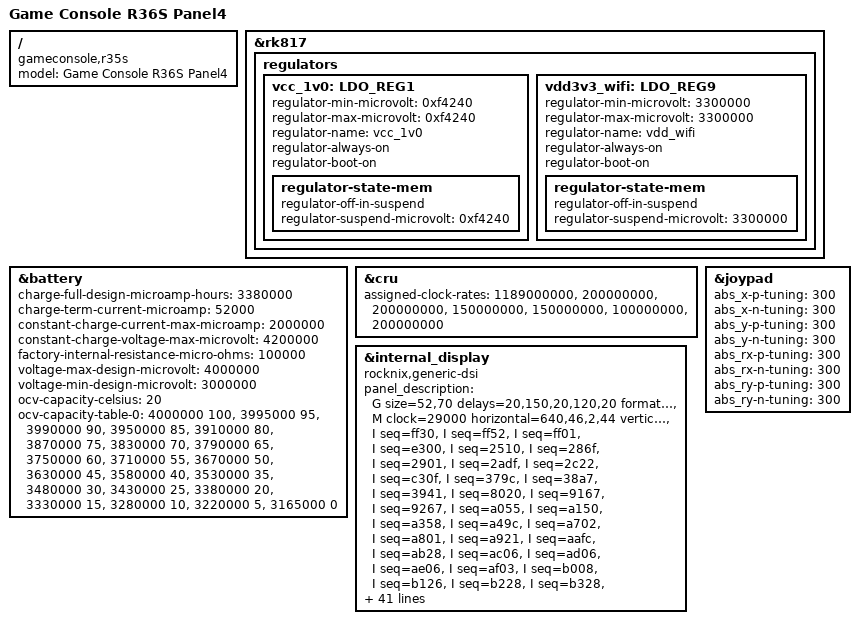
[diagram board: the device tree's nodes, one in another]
// SPDX-License-Identifier: (GPL-2.0+ OR MIT)
/*
* # Copyright (C) 2022-26 AURKNIX (https://github.com/AveyondFly)
*/

/dts-v1/;
#include "rk3326-gameconsole-r36s.dts"

/ {
	model = "Game Console R36S Panel4";
	compatible = "gameconsole,r35s", "gameconsole,r36s", "rockchip,rk3326";
};

&rk817 {
	regulators{
		vcc_1v0: LDO_REG1 {
			regulator-min-microvolt = <0xf4240>;
			regulator-max-microvolt = <0xf4240>;
			regulator-name = "vcc_1v0";
			regulator-always-on;
			regulator-boot-on;
			
			regulator-state-mem {
				regulator-off-in-suspend;
				regulator-suspend-microvolt = <0xf4240>;
			};
		};
		vdd3v3_wifi: LDO_REG9 {
			regulator-min-microvolt = <3300000>;
			regulator-max-microvolt = <3300000>;
			regulator-name = "vdd_wifi";
			regulator-always-on;
			regulator-boot-on;
			
			regulator-state-mem {
				regulator-off-in-suspend;
				regulator-suspend-microvolt = <3300000>;
			};
		};
	};
};

&battery {
	charge-full-design-microamp-hours = <3380000>;
	charge-term-current-microamp = <52000>;
	constant-charge-current-max-microamp = <2000000>;
	constant-charge-voltage-max-microvolt = <4200000>;
	factory-internal-resistance-micro-ohms = <100000>;
	voltage-max-design-microvolt = <4000000>;
	voltage-min-design-microvolt = <3000000>;

	ocv-capacity-celsius = <20>;
	ocv-capacity-table-0 = <4000000 100>, <3995000 95>, <3990000 90>, <3950000 85>,
		<3910000 80>, <3870000 75>, <3830000 70>, <3790000 65>,
		<3750000 60>, <3710000 55>, <3670000 50>, <3630000 45>,
		<3580000 40>, <3530000 35>, <3480000 30>, <3430000 25>,
		<3380000 20>, <3330000 15>, <3280000 10>, <3220000 5>,
		<3165000 0>;
};

&cru {
	assigned-clock-rates = <1189000000>,
	<200000000>, <200000000>,
	<150000000>, <150000000>,
	<100000000>, <200000000>;
};

&joypad {
	abs_x-p-tuning = <300>;
	abs_x-n-tuning = <300>;
	abs_y-p-tuning = <300>;
	abs_y-n-tuning = <300>;

	abs_rx-p-tuning = <300>;
	abs_rx-n-tuning = <300>;
	abs_ry-p-tuning = <300>;
	abs_ry-n-tuning = <300>;

};

&internal_display {
	compatible = "rocknix,generic-dsi";
	panel_description = 
	"G size=52,70 delays=20,150,20,120,20 format=rgb888 lanes=4 flags=0xe03",

	"M clock=29000 horizontal=640,46,2,44 vertical=480,165,2,13 default=1",

	"I seq=ff30",
	"I seq=ff52",
	"I seq=ff01",
	"I seq=e300",
	"I seq=2510",
	"I seq=286f",
	"I seq=2901",
	"I seq=2adf",
	"I seq=2c22",
	"I seq=c30f",
	"I seq=379c",
	"I seq=38a7",
	"I seq=3941",
	"I seq=8020",
	"I seq=9167",
	"I seq=9267",
	"I seq=a055",
	"I seq=a150",
	"I seq=a358",
	"I seq=a49c",
	"I seq=a702",
	"I seq=a801",
	"I seq=a921",
	"I seq=aafc",
	"I seq=ab28",
	"I seq=ac06",
	"I seq=ad06",
	"I seq=ae06",
	"I seq=af03",
	"I seq=b008",
	"I seq=b126",
	"I seq=b228",
	"I seq=b328",
	"I seq=b403",
	"I seq=b508",
	"I seq=b626",
	"I seq=b708",
	"I seq=b826",
	"I seq=2c22",
	"I seq=5c40",
	"I seq=c000",
	"I seq=c100",
	"I seq=c200",
	"I seq=ff30",
	"I seq=ff52",
	"I seq=ff02",
	"I seq=b002",
	"I seq=d002",
	"I seq=b10f",
	"I seq=d110",
	"I seq=b211",
	"I seq=d212",
	"I seq=b332",
	"I seq=d333",
	"I seq=b436",
	"I seq=d436",
	"I seq=b53c",
	"I seq=d53c",
	"I seq=b620",
	"I seq=d620",
	"I seq=b73e",
	"I seq=d73e",
	"I seq=b80e",
	"I seq=d80d",
	"I seq=b905",
	"I seq=d905",
	"I seq=ba11",
	"I seq=da12",
	"I seq=bb11",
	"I seq=db11",
	"I seq=bc13",
	"I seq=dc14",
	"I seq=bd14",
	"I seq=dd14",
	"I seq=be16",
	"I seq=de18",
	"I seq=bf0e",
	"I seq=df0f",
	"I seq=c017",
	"I seq=e017",
	"I seq=c107",
	"I seq=e108",
	"I seq=ff30",
	"I seq=ff52",
	"I seq=ff03",
	"I seq=088a",
	"I seq=098b",
	"I seq=3000",
	"I seq=3100",
	"I seq=3200",
	"I seq=3300",
	"I seq=3461",
	"I seq=35d4",
	"I seq=3624",
	"I seq=3703",
	"I seq=4086",
	"I seq=4187",
	"I seq=4284",
	"I seq=4385",
	"I seq=4411",
	"I seq=45de",
	"I seq=46dd",
	"I seq=4711",
	"I seq=48e0",
	"I seq=49df",
	"I seq=5082",
	"I seq=5183",
	"I seq=5280",
	"I seq=5381",
	"I seq=5411",
	"I seq=55e2",
	"I seq=56e1",
	"I seq=5711",
	"I seq=58e4",
	"I seq=59e3",
	"I seq=820f",
	"I seq=830f",
	"I seq=8400",
	"I seq=850f",
	"I seq=860f",
	"I seq=870e",
	"I seq=880e",
	"I seq=8906",
	"I seq=8a06",
	"I seq=8b07",
	"I seq=8c07",
	"I seq=8d04",
	"I seq=8e04",
	"I seq=8f05",
	"I seq=9005",
	"I seq=980f",
	"I seq=990f",
	"I seq=9a00",
	"I seq=9b0f",
	"I seq=9c0f",
	"I seq=9d0e",
	"I seq=9e0e",
	"I seq=9f06",
	"I seq=a006",
	"I seq=a107",
	"I seq=a207",
	"I seq=a304",
	"I seq=a404",
	"I seq=a505",
	"I seq=a605",
	"I seq=e002",
	"I seq=e152",
	"I seq=ff30",
	"I seq=ff52",
	"I seq=ff00",
	"I seq=3602",
	"I seq=1100",
	"I seq=2900",
	"I seq=11 wait=200",
	"I seq=29 wait=20";
};
